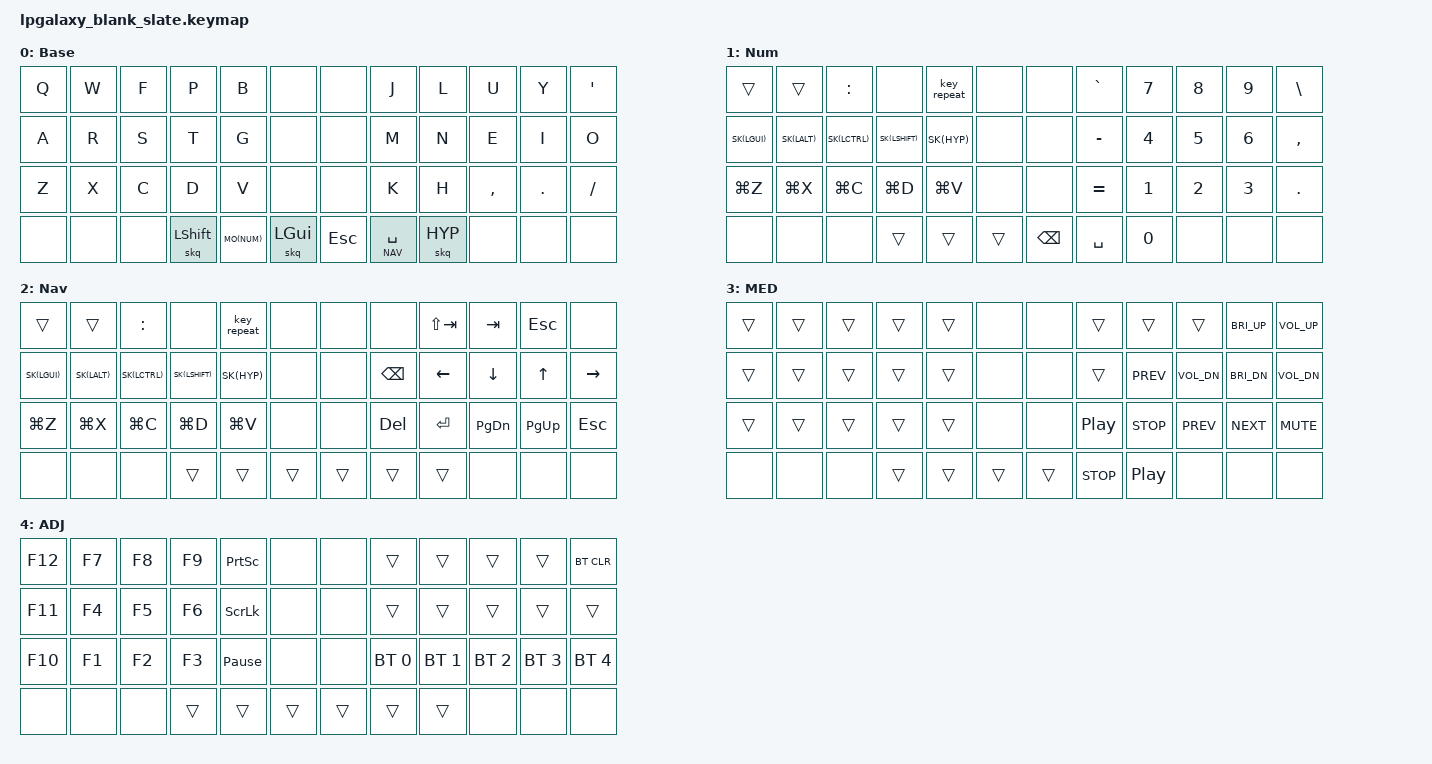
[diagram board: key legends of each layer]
/*
 * Copyright (c) 2022 Pete Johanson
 *
 * SPDX-License-Identifier: MIT
 */

#include <behaviors.dtsi>
#include <dt-bindings/zmk/keys.h>
#include <dt-bindings/zmk/bt.h>
#include <dt-bindings/zmk/outputs.h>

#define TBLE_ORTHO   1

#define BASE 0
#define NUM  1
#define NAV  2
#define MED  3
#define ADJ  4

#define XXX &none
#define ___ &trans

#define SK(KEY) &nk KEY KEY
#define MO(LAYER) &mo_tap LAYER F24
#define HYP LS(LC(LA(LGUI)))

// Apple "Globe" key
// https://github.com/zmkfirmware/zmk/issues/947
//#ifndef GLOBE
//  #define GLOBE CAPSLOCK
//#fi

// Sticky keys timeout after 1.5 seconds
#define STICKY_KEY_TIMEOUT 1500

&sk {
  release-after-ms = <STICKY_KEY_TIMEOUT>;
};

&lt {
  retro-tap;
  tapping_term_ms = <100>;
};

&caps_word {
  continue-list = <UNDERSCORE MINUS BACKSPACE>;
};

&kscan {
  debounce-period = <14>;
};

#define BT(n) BT_SEL n

/ {
    chosen {
       zmk,matrix_transform =
#ifdef TBLE_DUAL_2U
                       &dual_2u_transform;
#elif defined(TBLE_MIT)
                       &mit_transform;
#else
                       &ortho_transform;
#endif
    };

    combos {
        #include "combos.dtsi"
    };
    macros {
        #include "macros.dtsi"
    };

    behaviors {
        skq: sticky_key_quick_release {
            compatible = "zmk,behavior-sticky-key";
            label = "STICKY_KEY_QUICK_RELEASE";
            #binding-cells = <1>;
            bindings = <&kp>;
            quick-release;
            release-after-ms = <STICKY_KEY_TIMEOUT>;
        };

        // Sticky key on tap, normal key on hold
        // Useful for modifier-clicking without the modifier remaining active
        nk: not_so_sticky_key {
            compatible = "zmk,behavior-hold-tap";
            label = "NOT_SO_STICKY_KEY";
            #binding-cells = <2>;
            tapping_term_ms = <200>;
            flavor = "tap-preferred";
            bindings = <&kp>, <&sk>;
        };

        // A hold-tap that activates without delay (like `&mo`)
        mo_tap: mo_with_tap {
            compatible = "zmk,behavior-hold-tap";
            label = "MO_WITH_TAP";
            #binding-cells = <2>;
            tapping_term_ms = <0>;
            retro-tap;
            flavor = "hold-preferred";
            bindings = <&mo>, <&kp>;
        };
    };
    keymap {
        compatible = "zmk,keymap";

        base_layer {
            label = "Base";
            bindings = <
// ┏━━━━━━━━━━━┳━━━━━━━━━━━┳━━━━━━━━━━━┳━━━━━━━━━━━┳━━━━━━━━━━━┓                       ┏━━━━━━━━━━━┳━━━━━━━━━━━┳━━━━━━━━━━━┳━━━━━━━━━━━┳━━━━━━━━━━━┓
    &kp Q       &kp W       &kp F       &kp P       &kp B        &none      &none       &kp J       &kp L       &kp U       &kp Y       &kp APOS
// ┣━━━━━━━━━━━╋━━━━━━━━━━━╋━━━━━━━━━━━╋━━━━━━━━━━━╋━━━━━━━━━━━┫                       ┣━━━━━━━━━━━╋━━━━━━━━━━━╋━━━━━━━━━━━╋━━━━━━━━━━━╋━━━━━━━━━━━┫
    &kp A       &kp R       &kp S       &kp T       &kp G        &none      &none       &kp M       &kp N       &kp E       &kp I       &kp O
// ┣━━━━━━━━━━━╋━━━━━━━━━━━╋━━━━━━━━━━━╋━━━━━━━━━━━╋━━━━━━━━━━━┫                       ┣━━━━━━━━━━━╋━━━━━━━━━━━╋━━━━━━━━━━━╋━━━━━━━━━━━╋━━━━━━━━━━━┫
    &kp Z       &kp X       &kp C       &kp D       &kp V        &none      &none       &kp K       &kp H       &kp COMMA   &kp DOT     &kp FSLH
// ┗━━━━━━━━━━━┻━━━━━━━━━━━╋━━━━━━━━━━━╋━━━━━━━━━━━╋━━━━━━━━━━━┫                       ┣━━━━━━━━━━━╋━━━━━━━━━━━╋━━━━━━━━━━━╋━━━━━━━━━━━┻━━━━━━━━━━━┛
    &none       &none       &none       &skq LSHFT  MO(NUM)      &skq LGUI  &kp ESC     &lt NAV SPACE &skq HYP  &none      &none         &none
//                                     ┗━━━━━━━━━━━┻━━━━━━━━━━━┻━━━━━━━━━━┛┗━━━━━━━━━━━┻━━━━━━━━━━━┻━━━━━━━━━━━┛
            >;
        };

        num_layer {
            label = "Num";
            bindings = <
// ┏━━━━━━━━━━━┳━━━━━━━━━━━┳━━━━━━━━━━━┳━━━━━━━━━━━┳━━━━━━━━━━━┓                       ┏━━━━━━━━━━━┳━━━━━━━━━━━┳━━━━━━━━━━━┳━━━━━━━━━━━┳━━━━━━━━━━━┓
    ___         ___         &kp COLON   XXX         &key_repeat &none       &none       &kp GRAVE   &kp N7      &kp N8      &kp N9      &kp BSLH
// ┣━━━━━━━━━━━╋━━━━━━━━━━━╋━━━━━━━━━━━╋━━━━━━━━━━━╋━━━━━━━━━━━┫                       ┣━━━━━━━━━━━╋━━━━━━━━━━━╋━━━━━━━━━━━╋━━━━━━━━━━━╋━━━━━━━━━━━┫
    SK(LGUI)    SK(LALT)    SK(LCTRL)   SK(LSHIFT)  SK(HYP)     &none       &none       &kp MINUS   &kp N4      &kp N5      &kp N6      &kp COMMA
// ┣━━━━━━━━━━━╋━━━━━━━━━━━╋━━━━━━━━━━━╋━━━━━━━━━━━╋━━━━━━━━━━━┫                       ┣━━━━━━━━━━━╋━━━━━━━━━━━╋━━━━━━━━━━━╋━━━━━━━━━━━╋━━━━━━━━━━━┫
    &kp LG(Z)   &kp LG(X)   &kp LG(C)   &kp LG(D)   &kp LG(V)   &none       &none       &kp EQUAL   &kp N1      &kp N2      &kp N3      &kp DOT
// ┗━━━━━━━━━━━┻━━━━━━━━━━━╋━━━━━━━━━━━╋━━━━━━━━━━━╋━━━━━━━━━━━┫                       ┣━━━━━━━━━━━╋━━━━━━━━━━━╋━━━━━━━━━━━╋━━━━━━━━━━━┻━━━━━━━━━━━┛
    &none       &none       &none       ___         ___         ___         &kp BSPC    &kp SPACE   &kp N0      &none       &none       &none
//                                     ┗━━━━━━━━━━━┻━━━━━━━━━━━┻━━━━━━━━━━┛┗━━━━━━━━━━━┻━━━━━━━━━━━┻━━━━━━━━━━━┛
            >;
        };

        nav_layer {
            label = "Nav";
            bindings = <
// ┏━━━━━━━━━━━┳━━━━━━━━━━━┳━━━━━━━━━━━┳━━━━━━━━━━━┳━━━━━━━━━━━┓                       ┏━━━━━━━━━━━┳━━━━━━━━━━━┳━━━━━━━━━━━┳━━━━━━━━━━━┳━━━━━━━━━━━┓
    ___         ___         &kp COLON   XXX         &key_repeat &none       &none       XXX         &kp LS(TAB) &kp TAB     &kp ESC     XXX
// ┣━━━━━━━━━━━╋━━━━━━━━━━━╋━━━━━━━━━━━╋━━━━━━━━━━━╋━━━━━━━━━━━┫                       ┣━━━━━━━━━━━╋━━━━━━━━━━━╋━━━━━━━━━━━╋━━━━━━━━━━━╋━━━━━━━━━━━┫
    SK(LGUI)    SK(LALT)    SK(LCTRL)   SK(LSHIFT)  SK(HYP)     &none       &none       &kp BSPC    &kp LEFT    &kp DOWN    &kp UP      &kp RIGHT
// ┣━━━━━━━━━━━╋━━━━━━━━━━━╋━━━━━━━━━━━╋━━━━━━━━━━━╋━━━━━━━━━━━┫                       ┣━━━━━━━━━━━╋━━━━━━━━━━━╋━━━━━━━━━━━╋━━━━━━━━━━━╋━━━━━━━━━━━┫
    &kp LG(Z)   &kp LG(X)   &kp LG(C)   &kp LG(D)   &kp LG(V)   &none       &none       &kp DEL     &kp ENTER   &kp PG_DN   &kp PG_UP   &kp ESC
// ┗━━━━━━━━━━━┻━━━━━━━━━━━╋━━━━━━━━━━━╋━━━━━━━━━━━╋━━━━━━━━━━━┫                       ┣━━━━━━━━━━━╋━━━━━━━━━━━╋━━━━━━━━━━━╋━━━━━━━━━━━┻━━━━━━━━━━━┛
    &none       &none       &none       &trans      &trans      &trans      &trans      &trans      &trans      &none       &none       &none
//                                     ┗━━━━━━━━━━━┻━━━━━━━━━━━┻━━━━━━━━━━┛┗━━━━━━━━━━━┻━━━━━━━━━━━┻━━━━━━━━━━━┛
            >;
        };

        media_layer {
            label= "MED";
            bindings = <
    &trans     &trans     &trans      &trans  &trans    &none      &none       &trans           &trans           &trans       &kp C_BRI_UP &kp C_VOL_UP
    &trans     &trans     &trans      &trans  &trans    &none      &none       &trans           &kp C_PREV       &kp C_VOL_DN &kp C_BRI_DN &kp C_VOL_DN
    &trans     &trans     &trans      &trans  &trans    &none      &none       &kp C_PLAY_PAUSE &kp C_STOP       &kp C_PREV   &kp C_NEXT   &kp C_MUTE
    &none      &none      &none       &trans  &trans    &trans     &trans      &kp C_STOP       &kp C_PLAY_PAUSE &none        &none        &none
            >;
        };

        adjust_layer {
            label= "ADJ";
            bindings = <
    &kp F12    &kp F7     &kp F8    &kp F9    &kp PSCRN         &none      &none    &trans          &trans          &trans       &trans       &bt BT_CLR
    &kp F11    &kp F4     &kp F5    &kp F6    &kp SLCK          &none      &none    &trans          &trans          &trans       &trans       &trans
    &kp F10    &kp F1     &kp F2    &kp F3    &kp PAUSE_BREAK   &none      &none    &bt BT_SEL 0    &bt BT_SEL 1    &bt BT_SEL 2 &bt BT_SEL 3 &bt BT_SEL 4
    &none      &none      &none     &trans    &trans            &trans     &trans   &trans          &trans          &none        &none        &none
            >;
        };
    };
};

